# CPSW_CPSW3_08000000h register map
Vendor: Texas Instruments
Registers are 32-bit, read-write, reset 0x0 unless marked. A register's access mark holds for its fields unless they carry their own. Offsets are as the file gives them; [hi:lo] are bit positions; {n}, {i} and the like mark numbered series; 'fields as' and 'values as' point back to an identical list.

## cpsw3 (part 4 of 5)
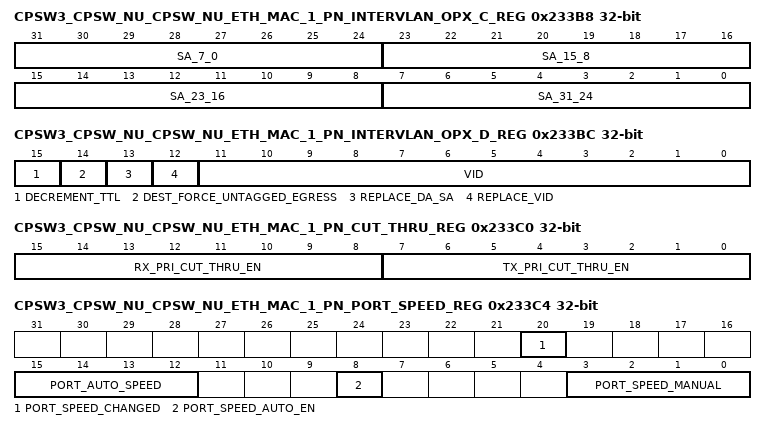
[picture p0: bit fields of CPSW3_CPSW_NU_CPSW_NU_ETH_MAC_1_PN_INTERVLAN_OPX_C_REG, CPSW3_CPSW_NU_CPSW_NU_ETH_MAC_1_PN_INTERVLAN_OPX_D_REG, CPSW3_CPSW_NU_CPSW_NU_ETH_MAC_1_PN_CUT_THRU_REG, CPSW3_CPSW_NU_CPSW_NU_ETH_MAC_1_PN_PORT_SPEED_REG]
0x233B8 CPSW3_CPSW_NU_CPSW_NU_ETH_MAC_1_PN_INTERVLAN_OPX_C_REG — Enet Port N Tx Egress InterVLAN C
  [31:24] SA_7_0 — Source Address bits 7:0 - DA byte 6 on wire
  [23:16] SA_15_8 — Source Address bits 15:8 - DA byte 5 on wire
  [15:8] SA_23_16 — Source Address bits 23:16 - DA byte 4 on wire
  [7:0] SA_31_24 — Source Address bits 31:24 - DA byte 3 on wire
0x233BC CPSW3_CPSW_NU_CPSW_NU_ETH_MAC_1_PN_INTERVLAN_OPX_D_REG — Enet Port N Tx Egress InterVLAN D
  [15] DECREMENT_TTL — Decrement Time To Live: When set, the Time To Live (TTL) field in the header is decremented.
  [14] DEST_FORCE_UNTAGGED_EGRESS — Destination VLAN Force Untagged Egress: When set, this bit indicates that the VLAN should be removed on egress for the routed packet.
  [13] REPLACE_DA_SA — Replace Destination Address and Source Address: When set this bit indicates that the routed packet destination address should be replaced by da[47:0] and the source address should be replaced by sa[47:0].
  [12] REPLACE_VID — Replace VLAN ID: When set this bit indicates that the VLAN ID should be replaced for the routed packet.
  [11:0] VID — VLAN ID
0x233C0 CPSW3_CPSW_NU_CPSW_NU_ETH_MAC_1_PN_CUT_THRU_REG — Enet Port N Cut Thru Priority Enable
  [15:8] RX_PRI_CUT_THRU_EN — Receive Cut Thru Priority Enable
  [7:0] TX_PRI_CUT_THRU_EN — Transmit Cut Thru Priority Enable
0x233C4 CPSW3_CPSW_NU_CPSW_NU_ETH_MAC_1_PN_PORT_SPEED_REG access per field — Enet Port Speed
  [20] PORT_SPEED_CHANGED ro
  [15:12] PORT_AUTO_SPEED ro — Detected Auto Speed
  [8] PORT_SPEED_AUTO_EN rw — Automatic Port Speed Enable
  [3:0] PORT_SPEED_MANUAL rw — Manual Port Speed
0x32000 CPSW3_CPSW_NU_CPSW_NU_EST_FETCH_LOC_j — The Revision Register contains the ID and revision information.
  [21:0] LOC — RAM Location
0x3A000 CPSW3_CPSW_NU_CPSW_NU_STAT_RXGOODFRAMES_j — Total number of good frames received
  [31:0] COUNT
0x3A004 CPSW3_CPSW_NU_CPSW_NU_STAT_RXBROADCASTFRAMES_j — Total number of good broadcast frames received
  [31:0] COUNT
0x3A008 CPSW3_CPSW_NU_CPSW_NU_STAT_RXMULTICASTFRAMES_j — Total number of good multicast frames received
  [31:0] COUNT
0x3A00C CPSW3_CPSW_NU_CPSW_NU_STAT_RXPAUSEFRAMES_j — Total number of pause frames received
  [31:0] COUNT
0x3A010 CPSW3_CPSW_NU_CPSW_NU_STAT_RXCRCERRORS_j — Total number of CRC errors frames received
  [31:0] COUNT
0x3A014 CPSW3_CPSW_NU_CPSW_NU_STAT_RXALIGNCODEERRORS_j — Total number of alignment/code errors received
  [31:0] COUNT
0x3A018 CPSW3_CPSW_NU_CPSW_NU_STAT_RXOVERSIZEDFRAMES_j — Total number of oversized frames received
  [31:0] COUNT
0x3A01C CPSW3_CPSW_NU_CPSW_NU_STAT_RXJABBERFRAMES_j — Total number of jabber frames received
  [31:0] COUNT
0x3A020 CPSW3_CPSW_NU_CPSW_NU_STAT_RXUNDERSIZEDFRAMES_j — Total number of undersized frames received
  [31:0] COUNT
0x3A024 CPSW3_CPSW_NU_CPSW_NU_STAT_RXFRAGMENTS_j — Total number of fragmented frames received
  [31:0] COUNT
0x3A028 CPSW3_CPSW_NU_CPSW_NU_STAT_ALE_DROP_j — Total number of frames dropped by the ALE
  [31:0] COUNT
0x3A02C CPSW3_CPSW_NU_CPSW_NU_STAT_ALE_OVERRUN_DROP_j — Total number of overrun frames dropped by the ALE
  [31:0] COUNT
0x3A030 CPSW3_CPSW_NU_CPSW_NU_STAT_RXOCTETS_j — Total number of received bytes in good frames
  [31:0] COUNT
0x3A034 CPSW3_CPSW_NU_CPSW_NU_STAT_TXGOODFRAMES_j — Total number of good frames transmitted
  [31:0] COUNT
0x3A038 CPSW3_CPSW_NU_CPSW_NU_STAT_TXBROADCASTFRAMES_j — Total number of good broadcast frames transmitted
  [31:0] COUNT
0x3A03C CPSW3_CPSW_NU_CPSW_NU_STAT_TXMULTICASTFRAMES_j — Total number of good multicast frames transmitted
  [31:0] COUNT
0x3A040 CPSW3_CPSW_NU_CPSW_NU_STAT_TXPAUSEFRAMES_j — Total number of pause frames transmitted
  [31:0] COUNT
0x3A044 CPSW3_CPSW_NU_CPSW_NU_STAT_TXDEFERREDFRAMES_j — Total number of deferred frames transmitted
  [31:0] COUNT
0x3A048 CPSW3_CPSW_NU_CPSW_NU_STAT_TXCOLLISIONFRAMES_j — Total number of transmitted frames experiencing a collision
  [31:0] COUNT
0x3A04C CPSW3_CPSW_NU_CPSW_NU_STAT_TXSINGLECOLLFRAMES_j — Total number of transmitted frames experiencing a single collision
  [31:0] COUNT
0x3A050 CPSW3_CPSW_NU_CPSW_NU_STAT_TXMULTCOLLFRAMES_j — Total number of transmitted frames experiencing multiple collisions
  [31:0] COUNT
0x3A054 CPSW3_CPSW_NU_CPSW_NU_STAT_TXEXCESSIVECOLLISIONS_j — Total number of transmitted frames abandoned due to excessive collisions
  [31:0] COUNT
0x3A058 CPSW3_CPSW_NU_CPSW_NU_STAT_TXLATECOLLISIONS_j — Total number of transmitted frames abandoned due to a late collision
  [31:0] COUNT
0x3A05C CPSW3_CPSW_NU_CPSW_NU_STAT_RXIPGERROR_j — Total number of receive inter-packet gap errors (10G only)
  [31:0] COUNT
0x3A060 CPSW3_CPSW_NU_CPSW_NU_STAT_TXCARRIERSENSEERRORS_j — Total number of transmitted frames that experienced a carrier loss
  [31:0] COUNT
0x3A064 CPSW3_CPSW_NU_CPSW_NU_STAT_TXOCTETS_j — Total number of bytes in all good frames transmitted
  [31:0] COUNT
0x3A068 CPSW3_CPSW_NU_CPSW_NU_STAT_OCTETFRAMES64_j — Total number of 64-byte frames received and transmitted
  [31:0] COUNT
0x3A06C CPSW3_CPSW_NU_CPSW_NU_STAT_OCTETFRAMES65T127_j — Total number of frames of size 65 to 127 bytes received and transmitted
  [31:0] COUNT
0x3A070 CPSW3_CPSW_NU_CPSW_NU_STAT_OCTETFRAMES128T255_j — Total number of frames of size 128 to 255 bytes received and transmitted
  [31:0] COUNT
0x3A074 CPSW3_CPSW_NU_CPSW_NU_STAT_OCTETFRAMES256T511_j — Total number of frames of size 256 to 511 bytes received and transmitted
  [31:0] COUNT
0x3A078 CPSW3_CPSW_NU_CPSW_NU_STAT_OCTETFRAMES512T1023_j — Total number of frames of size 512 to 1023 bytes received and transmitted
  [31:0] COUNT
0x3A07C CPSW3_CPSW_NU_CPSW_NU_STAT_OCTETFRAMES1024TUP_j — Total number of frames of size 1024 to rx_maxlen bytes received and 1024 bytes or greater transmitted
  [31:0] COUNT
0x3A080 CPSW3_CPSW_NU_CPSW_NU_STAT_NETOCTETS_j — Total number of bytes received and transmitted
  [31:0] COUNT
0x3A084 CPSW3_CPSW_NU_CPSW_NU_STAT_RX_BOTTOM_OF_FIFO_DROP_j — Receive Bottom of FIFO Drop
  [31:0] COUNT
0x3A088 CPSW3_CPSW_NU_CPSW_NU_STAT_PORTMASK_DROP_j — Total number of dropped frames received due to portmask
  [31:0] COUNT
0x3A08C CPSW3_CPSW_NU_CPSW_NU_STAT_RX_TOP_OF_FIFO_DROP_j — Receive Top of FIFO Drop
  [31:0] COUNT
0x3A090 CPSW3_CPSW_NU_CPSW_NU_STAT_ALE_RATE_LIMIT_DROP_j — Total number of dropped frames due to ALE Rate Limiting
  [31:0] COUNT
0x3A094 CPSW3_CPSW_NU_CPSW_NU_STAT_ALE_VID_INGRESS_DROP_j — Total number of dropped frames due to ALE VID Ingress
  [31:0] COUNT
0x3A098 CPSW3_CPSW_NU_CPSW_NU_STAT_ALE_DA_EQ_SA_DROP_j — Total number of dropped frames due to DA=SA
  [31:0] COUNT
0x3A09C CPSW3_CPSW_NU_CPSW_NU_STAT_ALE_BLOCK_DROP_j — Total number of dropped frames due to ALE Block Mode
  [31:0] COUNT
0x3A0A0 CPSW3_CPSW_NU_CPSW_NU_STAT_ALE_SECURE_DROP_j — Total number of dropped frames due to ALE Secure Mode
  [31:0] COUNT
0x3A0A4 CPSW3_CPSW_NU_CPSW_NU_STAT_ALE_AUTH_DROP_j — Total number of dropped frames due to ALE Authentication
  [31:0] COUNT
0x3A0A8 CPSW3_CPSW_NU_CPSW_NU_STAT_ALE_UNKN_UNI_j — ALE Receive Unknown Unicast
  [31:0] COUNT
0x3A0AC CPSW3_CPSW_NU_CPSW_NU_STAT_ALE_UNKN_UNI_BCNT_j — ALE Receive Unknown Unicast Bytecount
  [31:0] COUNT
0x3A0B0 CPSW3_CPSW_NU_CPSW_NU_STAT_ALE_UNKN_MLT_j — ALE Receive Unknown Multicast
  [31:0] COUNT
0x3A0B4 CPSW3_CPSW_NU_CPSW_NU_STAT_ALE_UNKN_MLT_BCNT_j — ALE Receive Unknown Multicast Bytecount
  [31:0] COUNT
0x3A0B8 CPSW3_CPSW_NU_CPSW_NU_STAT_ALE_UNKN_BRD_j — ALE Receive Unknown Broadcast
  [31:0] COUNT
0x3A0BC CPSW3_CPSW_NU_CPSW_NU_STAT_ALE_UNKN_BRD_BCNT_j — ALE Receive Unknown Broadcast Bytecount
  [31:0] COUNT
0x3A0C0 CPSW3_CPSW_NU_CPSW_NU_STAT_ALE_POL_MATCH_j — ALE Policer Matched
  [31:0] COUNT
0x3A0C4 CPSW3_CPSW_NU_CPSW_NU_STAT_ALE_POL_MATCH_RED_j — ALE Policer Matched and Condition Red
  [31:0] COUNT
0x3A0C8 CPSW3_CPSW_NU_CPSW_NU_STAT_ALE_POL_MATCH_YELLOW_j — ALE Policer Matched and Condition Yellow
  [31:0] COUNT
0x3A0CC CPSW3_CPSW_NU_CPSW_NU_STAT_ALE_MULT_SA_DROP_j — ALE Multicast Source Address Drop
  [31:0] COUNT — ALE Multicast Source Address drop
0x3A0D0 CPSW3_CPSW_NU_CPSW_NU_STAT_ALE_DUAL_VLAN_DROP_j — ALE Dual VLAN Drop
  [31:0] COUNT — ALE Dual VLAN drop
0x3A0D4 CPSW3_CPSW_NU_CPSW_NU_STAT_ALE_LEN_ERROR_DROP_j — ALE Length Error Drop
  [31:0] COUNT — ALE Length Error drop
0x3A0D8 CPSW3_CPSW_NU_CPSW_NU_STAT_ALE_IP_NEXT_HDR_DROP_j — ALE IP Next Header Drop
  [31:0] COUNT — ALE Next Header drop
0x3A0DC CPSW3_CPSW_NU_CPSW_NU_STAT_ALE_IPV4_FRAG_DROP_j — ALE IPV4 Frag Drop
  [31:0] COUNT — ALE IPV4 Fragment drop
0x3A140 CPSW3_CPSW_NU_CPSW_NU_STAT_IET_RX_ASSEMBLY_ERROR_REG_j — IET Receive Assembly Error
  [31:0] IET_RX_ASSEMBLY_ERROR
0x3A144 CPSW3_CPSW_NU_CPSW_NU_STAT_IET_RX_ASSEMBLY_OK_REG_j — IET Receive Assembly Ok
  [31:0] IET_RX_ASSEMBLY_OK
0x3A148 CPSW3_CPSW_NU_CPSW_NU_STAT_IET_RX_SMD_ERROR_REG_j — IET Receive Smd Error
  [31:0] IET_RX_SMD_ERROR
0x3A14C CPSW3_CPSW_NU_CPSW_NU_STAT_IET_RX_FRAG_REG_j — IET Receive Frag
  [31:0] IET_RX_FRAG
0x3A150 CPSW3_CPSW_NU_CPSW_NU_STAT_IET_TX_HOLD_REG_j — IET Transmit Hold
  [31:0] IET_TX_HOLD
0x3A154 CPSW3_CPSW_NU_CPSW_NU_STAT_IET_TX_FRAG_REG_j — IET Transmit Frag
  [31:0] IET_TX_FRAG
0x3A17C CPSW3_CPSW_NU_CPSW_NU_STAT_TX_MEMORY_PROTECT_ERROR_j — Transmit Memory Protect CRC Error
  [7:0] COUNT
0x3A180 CPSW3_CPSW_NU_CPSW_NU_STAT_ENET_PN_TX_PRI_REG_j_k — ENET Port n PRIORITY N Packet Count
  [31:0] PN_TX_PRIN — ENET TX Priority Packet Count
0x3A1A0 CPSW3_CPSW_NU_CPSW_NU_STAT_ENET_PN_TX_PRI_BCNT_REG_j_k — ENET Port n PRIORITY N Packet Byte Count
  [31:0] PN_TX_PRIN_BCNT
0x3A1C0 CPSW3_CPSW_NU_CPSW_NU_STAT_ENET_PN_TX_PRI_DROP_REG_j_k — ENET Port n PRIORITY N Packet Drop Count
  [31:0] PN_TX_PRIN_DROP
0x3A1E0 CPSW3_CPSW_NU_CPSW_NU_STAT_ENET_PN_TX_PRI_DROP_BCNT_REG_j_k — ENET Port n PRIORITY N Packet Drop Byte Count
  [31:0] PN_TX_PRIN_DROP_BCNT
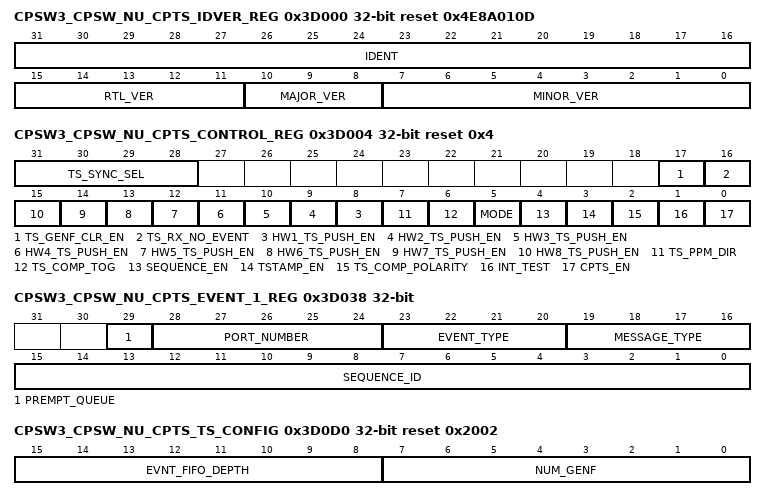
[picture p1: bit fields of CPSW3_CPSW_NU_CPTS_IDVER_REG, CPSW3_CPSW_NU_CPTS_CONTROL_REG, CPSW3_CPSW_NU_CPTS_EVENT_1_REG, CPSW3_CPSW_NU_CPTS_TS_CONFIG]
0x3D000 CPSW3_CPSW_NU_CPTS_IDVER_REG ro reset 0x4E8A010D — Identification and Version Register
  [31:16] IDENT — Identification value
  [15:11] RTL_VER — RTL version value
  [10:8] MAJOR_VER — Major version value
  [7:0] MINOR_VER — Minor version value
0x3D004 CPSW3_CPSW_NU_CPTS_CONTROL_REG reset 0x4 — Time Sync Control Register
  [31:28] TS_SYNC_SEL — TS_SYNC output time stamp counter bit select. 0h TS_SYNC disabled.1h-Fh TS_SYNC is time stamp counter bits 31 (Fh) down to 17 (1h).
  [17] TS_GENF_CLR_EN — GENF (and ESTF) Clear Enable. 0h A CPTS_GENFn output is not cleared when the associated CPSW_GENF_LENGTH_REG_l[31:0] is cleared to zero.1h A CPTS_GENFn output is cleared when the associated CPSW_GENF_LENGTH_REG_l[31:0] is cleared to zero.
  [16] TS_RX_NO_EVENT — Timestamp Ethernet Receive produces no events. 0h Ethernet receive timesync events enabled.1h Ethernet receive timesync events disabled.
  [n+7] HW{n}_TS_PUSH_EN (n=1..8) — Hardware push {n} enable.
  [7] TS_PPM_DIR — PPM Correction Direction. 0h Increase the TIME_STAMP[63:0] value (CPSW_CPTS_EVENT_0_REG and CPSW_CPTS_EVENT_3_REG) by the PPM value.1h Decrease the TIME_STAMP[63:0] value (CPSW_CPTS_EVENT_0_REG and CPSW_CPTS_EVENT_3_REG and) by the PPM value.
  [6] TS_COMP_TOG — Time Stamp Compare Toggle mode. 0h TS_COMP is in non-toggle mode.1h TS_COMP is in toggle mode.
  [5] MODE — 64-Bit Mode. 0h The time stamp is 32-bits with the upper 32-bits forced to zero.1h The time stamp is 64-bits.
  [4] SEQUENCE_EN — Sequence Enable. 0h The time stamp value increments with the selected RFTCLK1h The time stamp for received packets is the sequence number of the received packet (first packet is 1, second packet is 2, etc).
  [3] TSTAMP_EN — Host Receive Time Stamp Enable. 0h Time stamps are disabled on received packets to host.1h Time stamps enabled on received packets to host (PCIE_CPTS_CONTROL_REG[0] CPTS_EN must be set).
  [2] TS_COMP_POLARITY — TS_COMP Polarity. 0h TS_COMP is asserted low.1h TS_COMP is asserted high.
  [1] INT_TEST — Interrupt Test. When set, this bit allows the raw interrupt to be written to facilitate interrupt test.
  [0] CPTS_EN — Time Sync Enable. When disabled (cleared to zero), the RCLK domain is held in reset.
0x3D008 CPSW3_CPSW_NU_CPTS_RFTCLK_SEL_REG — RFTCLK Select Register
  [4:0] RFTCLK_SEL — Reference clock select. This bit field is used to control an external multiplexer that selects one out of 8 clocks for time sync reference. 0h Selects CPSWHSDIV_CLKOUT2 clock1h Selects MAINHSDIV_CLKOUT3 clock2h Selects MCU_CPTS0_RFT_CLK I/O pin3h Selects CPTS0_RFT_CLK I/O pin4h Selects MCU_EXT_REFCLK0 I/O pin5h Selects EXT_REFCLK1 I/O pin6h Selects PCIE0_TXI0_CLK clock7h Selects PCIE1_TXI0_CLK clock The RFTCLK_SEL value can be written only when the [0] CPTS_EN and [3] TSTAMP_EN bits are cleared to zero in the CPSW_CPTS_CONTROL_REG register.
0x3D00C CPSW3_CPSW_NU_CPTS_TS_PUSH_REG wo — Time Stamp Event Push Register
  [0] TS_PUSH — Time stamp event push. When a logic high is written to this bit a time stamp event is pushed onto the event FIFO. The time stamp value is the time of the write of this register, not the time of the event read. The time stamp value can then be read on interrupt via the event registers. Software should not push a second time stamp event onto the event FIFO until the first time stamp value has been read from the event FIFO (there should be only one time stamp event in the event FIFO at any given time). This bit is write only and always reads zero.
0x3D010 CPSW3_CPSW_NU_CPTS_TS_LOAD_VAL_REG — Time Stamp Load Low Value Register
  [31:0] TS_LOAD_VAL — Time stamp load low value
0x3D014 CPSW3_CPSW_NU_CPTS_TS_LOAD_EN_REG wo — Time Stamp Load Enable Register
  [0] TS_LOAD_EN — Time Stamp Load Enable. Writing a one to this bit enables the time stamp value to be written with the value in CPSW_CPTS_TS_LOAD_VAL_REG/ CPSW_CPTS_TS_LOAD_HIGH_VAL_REG. This bit is write only and will be cleared by the hardware after one clock. The upper 32-bits of the time stamp (CPSW_CPTS_TS_LOAD_HIGH_VAL_REG) are forced to zero in 32-bit mode.
0x3D018 CPSW3_CPSW_NU_CPTS_TS_COMP_VAL_REG — Time Stamp Comparison Low Value Register
  [31:0] TS_COMP_VAL — Time Stamp Comparison Low Value. Writing a non-zero value to the CPSW_CPTS_TS_COMP_LEN_REG[31-0] TS_COMP_LENGTH register causes a pulse of TS_COMP_LENGTH RCLK periods on the TS_COMP output and a comparison event when the TIME_STAMP counter value is equivalent to CPSW_CPTS_TS_COMP_VAL_REG[31-0] TS_COMP_VAL.
0x3D01C CPSW3_CPSW_NU_CPTS_TS_COMP_LEN_REG — Time Stamp Comparison Length Register
  [31:0] TS_COMP_LENGTH — Time Stamp Comparison Length. Writing a non-zero value to this field enables the time stamp comparison event and output. This value should be zero when the CPSW_GENF_COMP_LOW_REG_L[31-0] COMP_LOW and CPSW_GENF_COMP_HIGH_REG_L[31-0] COMP_HIGH registers are written.
0x3D020 CPSW3_CPSW_NU_CPTS_INTSTAT_RAW_REG — Interrupt Status Register Raw
  [0] TS_PEND_RAW — TS_PEND_RAW int read (before enable). Writable when CPSW_CPTS_CONTROL_REG[1] INT_TEST = 1h A one in this bit indicates that there are one or more events in the event FIFO.
0x3D024 CPSW3_CPSW_NU_CPTS_INTSTAT_MASKED_REG ro — Interrupt Status Register Masked
  [0] TS_PEND — TS_PEND masked interrupt read (after enable)
0x3D028 CPSW3_CPSW_NU_CPTS_INT_ENABLE_REG — Interrupt Enable Register
  [0] TS_PEND_EN — TS_PEND masked interrupt enable
0x3D02C CPSW3_CPSW_NU_CPTS_TS_COMP_NUDGE_REG — Time Stamp Comparison Nudge Register
  [7:0] NUDGE — Time stamp Comparison Nudge Value. This two's complement number is added to the CPSW_CPTS_TS_COMP_LEN_REG[31-0] TS_COMP_LENGTH value to increase or decrease the TS_COMP length by the CPSW_CPTS_TS_COMP_NUDGE_REG[7-0] NUDGE amount. Only a single high or low time is adjusted and the CPSW_CPTS_TS_COMP_NUDGE_REG value is cleared to zero when the nudge has occurred.
0x3D030 CPSW3_CPSW_NU_CPTS_EVENT_POP_REG wo — Event Pop Register
  [0] EVENT_POP — Event Pop. When a logic high is written to this bit an event is popped off the event FIFO. The event FIFO pop occurs as part of the interrupt process after the event has been read from the CPSW_CPTS_EVENT_0_REG to CPSW_CPTS_EVENT_3_REG registers. Popping an event discards the event and causes the next event, if any, to be moved to the top of the FIFO ready to be read by software on interrupt.
0x3D034 CPSW3_CPSW_NU_CPTS_EVENT_0_REG ro — Event 0 Register
  [31:0] TIME_STAMP — Time Stamp. The time stamp is valid for transmit, receive, and time stamp push event types. The time stamp value is not valid for counter roll event types.
0x3D038 CPSW3_CPSW_NU_CPTS_EVENT_1_REG ro — Event 1 Register
  [29] PREMPT_QUEUE
  [28:24] PORT_NUMBER — Port Number. Indicates the port number (encoded) of an Ethernet event or the encoded hardware time stamp number.
  [23:20] EVENT_TYPE — Time Sync Event Type 0h Time Stamp Push Event1h Time Stamp Rollover Event2h Time Stamp Half Rollover Event3h Hardware Time Stamp Push Event4h Ethernet Receive Event5h Ethernet Transmit Event6h Time Stamp Compare Event7h Host Transmit Event8h-Fh Reserved
  [19:16] MESSAGE_TYPE — Message type. The message type value that was contained in an Ethernet transmit or receive time sync packet. This field is valid only for Ethernet transmit or receive events.
  [15:0] SEQUENCE_ID — Sequence ID. The 16-bit sequence id is the value that was contained in an Ethernet transmit or receive time sync packet. This field is valid only for Ethernet transmit or receive events.
0x3D03C CPSW3_CPSW_NU_CPTS_EVENT_2_REG ro — Event 2 Register
  [7:0] DOMAIN — Domain. The 8-bit domain is the value that was contained in an Ethernet transmit or receive time sync packet. This field is valid only for Ethernet transmit or receive events.
0x3D040 CPSW3_CPSW_NU_CPTS_EVENT_3_REG ro — Event 3 Register
  [31:0] TIME_STAMP — Time Stamp. The time stamp upper 32-bits are valid for transmit, receive, and time stamp push event types. This value is zero in 32-bit mode.
0x3D044 CPSW3_CPSW_NU_CPTS_TS_LOAD_HIGH_VAL_REG — Time Stamp Load High Value Register
  [31:0] TS_LOAD_VAL — Time Stamp Load high Value. Writing the CPSW_CPTS_TS_LOAD_EN_REG[0] TS_LOAD_EN bit causes the value contained in this register to be written into the time stamp. The time stamp value is read by initiating a time stamp push event, not by reading this register. When reading this register, the value read is not the time stamp, but is the value that was last written to this register. This value is unused in 32-bit mode
0x3D048 CPSW3_CPSW_NU_CPTS_TS_COMP_HIGH_VAL_REG — Time Stamp Comparison High Value Register
  [31:0] TS_COMP_HIGH_VAL — Time Stamp Comparison High Value. Writing a non-zero value to the CPSW_CPTS_TS_COMP_LEN_REG[31-0] TS_COMP_LENGTH register causes a pulse of TS_COMP_LENGTH RCLK periods on the TS_COMP output and a comparison event when the [31-0]TIME_STAMP counter value is equivalent to CPSW_CPTS_TS_COMP_VAL_REG[31-0] TS_COMP_VAL and CPSW_CPTS_TS_COMP_HIGH_VAL_REG[31-0] TS_COMP_HIGH_VAL. This value is unused in 32-bit mode. The upper 32-bits in CPSW_CPTS_TS_COMP_HIGH_VAL_REG register should be written before the lower 32-bits in the CPSW_CPTS_TS_COMP_VAL_REG register.
0x3D04C CPSW3_CPSW_NU_CPTS_TS_ADD_VAL_REG — TS Add Value Register
  [2:0] ADD_VAL — The ts_add_value[2:0] is added to 1 to comprise the time stamp increment value. The time stamp increment value is added to the current time stamp (time_stamp[63:0]) on each RCLK. The time stamp increment value can be adjusted by nudge and ppm also. The CPSW_CPTS_TS_ADD_VAL_REG[2-0] ADD_VAL value may be non-zero in 64-bit mode only.
0x3D050 CPSW3_CPSW_NU_CPTS_TS_PPM_LOW_VAL_REG — Time Stamp PPM Low Value Register
  [31:0] TS_PPM_LOW_VAL — Time Stamp PPM Low Value. The 64-bit PPM value takes effect when this low value is written. The high value should be written first. Note: There should be at least 10 clocks in between writes to the low register to ensure that the previous operation has been seen.
0x3D054 CPSW3_CPSW_NU_CPTS_TS_PPM_HIGH_VAL_REG — Time Stamp PPM High Value Register
  [9:0] TS_PPM_HIGH_VAL — Time Stamp PPM High Value. This value should be written first (before the low value is written). The minimum value of the Time Stamp PPM is 0x400 (all 42 bits: CPSW_CPTS_TS_PPM_LOW_VAL_REG[31-0] TS_PPM_LOW_VAL and CPSW_CPTS_TS_PPM_HIGH_VAL_REG[9-0] TS_PPM_HIGH_VAL).
0x3D058 CPSW3_CPSW_NU_CPTS_TS_NUDGE_VAL_REG — Time Stamp Nudge Value Register
  [7:0] TS_NUDGE_VAL — Time stamp Nudge Value. This two's complement number is added to the CPSW_CPTS_EVENT_0_REG[31-0] TIME_STAMP and CPSW_CPTS_EVENT_3_REG[[31-0] TIME_STAMP value to increase or decrease the time stamp value by the CPSW_CPTS_TS_NUDGE_VAL_REG[7-0] TS_NUDGE_VAL amount. The TS_NUDGE_VAL value is cleared to zero when the nudge has occurred. The minimum value of the Time Stamp PPM is 0x400 (all 42 bits: CPSW_CPTS_TS_PPM_LOW_VAL_REG[31-0] TS_PPM_LOW_VAL and CPSW_CPTS_TS_PPM_HIGH_VAL_REG[9-0] TS_PPM_HIGH_VAL).
0x3D0D0 CPSW3_CPSW_NU_CPTS_TS_CONFIG ro reset 0x2002 — Time Stamp Configuration Read
  [15:8] EVNT_FIFO_DEPTH — The Event FIFO Depth
  [7:0] NUM_GENF — The number of CPTS GENF outputs
0x3D0E0 CPSW3_CPSW_NU_CPTS_TS_GENF_COMP_LOW_REG_j — Time Stamp Generate Function Comparison Low Value
  [31:0] COMP_LOW — Time Stamp Generate Function Comparison Low Value (lower 32- bits). This value should be written after the upper 32-bits. The CPSW_GENF_COMP_HIGH_REG_l and CPSW_GENF_COMP_LOW_REG_l should only be written when the CPSW_GENF_LENGTH_REG_l[31-0] LENGTH value is zero.
0x3D0E4 CPSW3_CPSW_NU_CPTS_TS_GENF_COMP_HIGH_REG_j — Time Stamp Generate Function Comparison high Value
  [31:0] COMP_HIGH — Time Stamp Generate Function Comparison High Value (upper 32- bits). This value should be written before the lower 32-bits. The CPSW_GENF_COMP_HIGH_REG_l and CPSW_GENF_COMP_LOW_REG_l should only be written when the CPSW_GENF_LENGTH_REG_l[31-0] LENGTH value is zero.
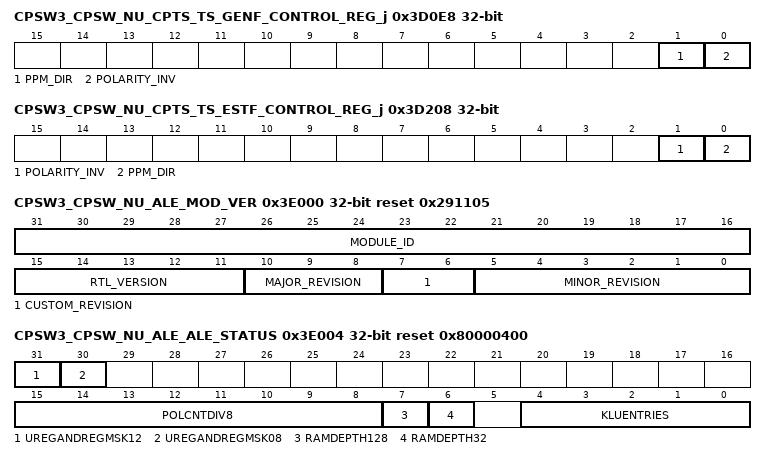
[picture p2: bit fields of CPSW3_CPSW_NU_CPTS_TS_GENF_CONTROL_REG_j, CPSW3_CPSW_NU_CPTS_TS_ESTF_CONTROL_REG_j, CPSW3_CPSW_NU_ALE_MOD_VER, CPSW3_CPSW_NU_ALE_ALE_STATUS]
0x3D0E8 CPSW3_CPSW_NU_CPTS_TS_GENF_CONTROL_REG_j — Time Stamp Generate Function Control
  [1] PPM_DIR — Time Stamp Generate Function PPM Direction. 0h A single RCLK is added to the generate function counter at the PPM rate which has the effect of decreasing the generate function frequency by the PPM amount.1h A single RCLK is subtracted from the generate function counter at the PPM rate which has the effect of increasing the generate function frequency by the PPM amount.
  [0] POLARITY_INV — Time Stamp Generate Function Polarity Invert 0h The output TS_GENFn signal asserts low1h The output TS_GENFn signal asserts high
0x3D0EC CPSW3_CPSW_NU_CPTS_TS_GENF_LENGTH_REG_j — Time Stamp Generate Function Length Value
  [31:0] LENGTH
0x3D0F0 CPSW3_CPSW_NU_CPTS_TS_GENF_PPM_LOW_REG_j — Time Stamp Generate Function PPM Low Value
  [31:0] PPM_LOW — Time Stamp ESTFn (n = 1 to 2) Generate Function PPM Low Value. The 64-bit PPM value takes effect when this low value is written. The high value should be written first.
0x3D0F4 CPSW3_CPSW_NU_CPTS_TS_GENF_PPM_HIGH_REG_j — Time Stamp Generate Function PPM High Value
  [9:0] PPM_HIGH — Time Stamp Generate Function PPM High Value. This value should be written first (before the low value is written).
0x3D0F8 CPSW3_CPSW_NU_CPTS_TS_GENF_NUDGE_REG_j — Time Stamp Generate Function Nudge Value
  [7:0] NUDGE — Time Stamp Generate Function Nudge Value. This two's complement number is added to the generate counter value to increase or decrease the length by the CPSW_GENF_NUDGE_REG_l[7-0] NUDGE amount. Only a single high or low time is adjusted and the CPSW_GENF_NUDGE_REG_l value is cleared to zero when the nudge has occurred.
0x3D200 CPSW3_CPSW_NU_CPTS_TS_ESTF_COMP_LOW_REG_j — Time Stamp ESTF Generate Function Comparison Low Value
  [31:0] COMP_LOW — ESTFn comparison value lower 32-bits. This value should be written after the upper 32-bits. The ts_ESTFn_comp high and low should only be written when the ts_ESTFn_length value is zero.
0x3D204 CPSW3_CPSW_NU_CPTS_TS_ESTF_COMP_HIGH_REG_j — Time Stamp ESTF Generate Function Comparison high Value
  [31:0] COMP_HIGH — ESTFn comparison value upper 32-bits. This value should be written before the lower 32-bits are written. The ts_ESTFn_comp high and low should only be written when the ts_ESTFn_length value is zero.
0x3D208 CPSW3_CPSW_NU_CPTS_TS_ESTF_CONTROL_REG_j — Time Stamp ESTF Generate Function Control
  [1] POLARITY_INV — Time Stamp Generate Function (ESTFn, where n = 1 to 2) Polarity Invert. 0h The output TS_ESTFn signal asserts low1h The output TS_ESTFn signal asserts high
  [0] PPM_DIR — Time Stamp Generate Function (ESTFn, where n = 1 to 2) PPM Direction. 0h A single RCLK is added to the generate function counter at the PPM rate which has the effect of decreasing the generate function frequency by the PPM amount.1h A single RCLK is subtracted from the generate function counter at the PPM rate which has the effect of increasing the generate function frequency by the PPM amount.
0x3D20C CPSW3_CPSW_NU_CPTS_TS_ESTF_LENGTH_REG_j — Time Stamp ESTF Generate Function Length Value
  [31:0] LENGTH — Time Stamp ESTFn (n = 1 to 2) Generate Function Length Value.
0x3D210 CPSW3_CPSW_NU_CPTS_TS_ESTF_PPM_LOW_REG_j — Time Stamp ESTF Generate Function PPM Low Value
  fields as CPSW3_CPSW_NU_CPTS_TS_GENF_PPM_LOW_REG_j
0x3D214 CPSW3_CPSW_NU_CPTS_TS_ESTF_PPM_HIGH_REG_j — Time Stamp ESTF Generate Function PPM High Value
  [9:0] PPM_HIGH — Time Stamp ESTFn (n = 1 to 2) Generate Function PPM High Value. This value should be written first (before the low value is written).
0x3D218 CPSW3_CPSW_NU_CPTS_TS_ESTF_NUDGE_REG_j — Time Stamp ESTF Generate Function Nudge Value
  [7:0] NUDGE — Time Stamp ESTFn (n = 1 to 2) Generate Function Nudge Value. This two's complement number is added to the generate counter value to increase or decrease the length by the CPSW_ESTF_NUDGE_REG_l[7-0] NUDGE amount. Only a single high or low time is adjusted and the CPSW_ESTF_NUDGE_REG_l value is cleared to zero when the nudge has occurred.
0x3E000 CPSW3_CPSW_NU_ALE_MOD_VER ro reset 0x291105 — The Module and Version Register identifies the module identifier and revision of the ALE_3g512ie module.
  [31:16] MODULE_ID — ALE_3g512ie module ID.
  [15:11] RTL_VERSION
  [10:8] MAJOR_REVISION
  [7:6] CUSTOM_REVISION
  [5:0] MINOR_REVISION
0x3E004 CPSW3_CPSW_NU_ALE_ALE_STATUS ro reset 0x80000400 — The ALE status provides information on the ALE configuration and state. The ~iramdepth is used to determine how IPv6 entries are stored in the table. IPv6 entries are stored in two entries where IPv6 Entry hi is designated by the odd slice index and lo is designated by the even slice index. The slice index is above the ram depth like {SlixeIndex,RamIndex}. So for a 64 deep RAM index of 0x005, the Hi portion of the IPv6 entry is located at 0x005|0x040 and the Lo portion is located at 0x005&(~0x040).
  [31] UREGANDREGMSK12 — When set, the unregistered multicast field is a mask versus an index on 12 bit boundary in the ALE table.
  [30] UREGANDREGMSK08 — When set, the unregistered multicast field is a mask versus an index on 8 bit boundary in the ALE table.
  [15:8] POLCNTDIV8 — This is the number of Classifiers the ALE implements divided by 8. A value of 4 indicates 32 policer engines total.
  [7] RAMDEPTH128 — The number of ALE entries per slice of the table when this is set it indicates the depth is 128 if both ramdepth128 and ramdepth32 are zero the depth is 64.
  [6] RAMDEPTH32 — The number of ALE entries per slice of the table when this is set it indicates the depth is 32 if both ramdepth128 and ramdepth32 are zero the depth is 64.
  [4:0] KLUENTRIES — This is the number of table entries total divided by 1024. A value of 1 indicates 1024 table entries. A value of 8 indicates 8192 table entries.
